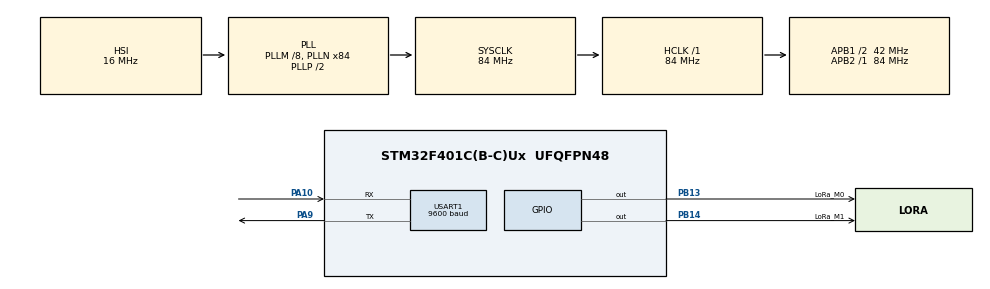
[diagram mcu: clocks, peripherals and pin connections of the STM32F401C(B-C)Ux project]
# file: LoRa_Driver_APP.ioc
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Dma.Request0=USART1_RX
Dma.USART1_RX.0.Direction=DMA_PERIPH_TO_MEMORY
Dma.USART1_RX.0.FIFOMode=DMA_FIFOMODE_DISABLE
Dma.USART1_RX.0.Instance=DMA2_Stream2
Dma.USART1_RX.0.MemDataAlignment=DMA_MDATAALIGN_BYTE
Dma.USART1_RX.0.MemInc=DMA_MINC_ENABLE
Dma.USART1_RX.0.Mode=DMA_NORMAL
Dma.USART1_RX.0.PeriphDataAlignment=DMA_PDATAALIGN_BYTE
Dma.USART1_RX.0.PeriphInc=DMA_PINC_DISABLE
Dma.USART1_RX.0.Priority=DMA_PRIORITY_LOW
Mcu.Family=STM32F4
Mcu.Name=STM32F401C(B-C)Ux
Mcu.Package=UFQFPN48
NVIC.DMA2_Stream2_IRQn=true\:0\:0\:false\:false\:true\:false\:true\:true
NVIC.PriorityGroup=NVIC_PRIORITYGROUP_4
NVIC.USART1_IRQn=true\:0\:0\:false\:false\:true\:true\:true\:true
PA10.Mode=Asynchronous
PA10.Signal=USART1_RX
PA13.Mode=Serial_Wire
PA13.Signal=SYS_JTMS-SWDIO
PA14.Mode=Serial_Wire
PA14.Signal=SYS_JTCK-SWCLK
PA9.Mode=Asynchronous
PA9.Signal=USART1_TX
PB13.GPIO_Label=LoRa_M0
PB13.Signal=GPIO_Output
PB14.GPIO_Label=LoRa_M1
PB14.Signal=GPIO_Output
PH0\ -\ OSC_IN.Mode=HSE-External-Oscillator
PH0\ -\ OSC_IN.Signal=RCC_OSC_IN
PH1\ -\ OSC_OUT.Mode=HSE-External-Oscillator
PH1\ -\ OSC_OUT.Signal=RCC_OSC_OUT
ProjectManager.HeapSize=0x200
ProjectManager.StackSize=0x400
ProjectManager.TargetToolchain=STM32CubeIDE
RCC.48MHZClocksFreq_Value=42000000
RCC.AHBFreq_Value=84000000
RCC.APB1CLKDivider=RCC_HCLK_DIV2
RCC.APB1Freq_Value=42000000
RCC.APB1TimFreq_Value=84000000
RCC.APB2Freq_Value=84000000
RCC.APB2TimFreq_Value=84000000
RCC.CortexFreq_Value=84000000
RCC.HCLKFreq_Value=84000000
RCC.HSE_VALUE=25000000
RCC.HSI_VALUE=16000000
RCC.LSE_VALUE=32768
RCC.PLLM=8
RCC.PLLN=84
RCC.SYSCLKFreq_VALUE=84000000
RCC.SYSCLKSource=RCC_SYSCLKSOURCE_PLLCLK
RCC.VCOOutputFreq_Value=168000000
USART1.BaudRate=9600
USART1.VirtualMode=VM_ASYNC
board=custom

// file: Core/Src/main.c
/* USER CODE BEGIN Header */
/**
  ******************************************************************************
  * @file           : main.c
  * @brief          : Main program body
  ******************************************************************************
  * @attention
  *
  * Copyright (c) 2024 STMicroelectronics.
  * All rights reserved.
  *
  * This software is licensed under terms that can be found in the LICENSE file
  * in the root directory of this software component.
  * If no LICENSE file comes with this software, it is provided AS-IS.
  *
  ******************************************************************************
  */
/* USER CODE END Header */
#include "main.h"

/* USER CODE BEGIN Includes */
#include "SubSys_WirelessCom_Config.h"
#include "SubSys_WirelessCom_App.h"
/* USER CODE END Includes */

UART_HandleTypeDef huart1;
DMA_HandleTypeDef hdma_usart1_rx;

/* USER CODE BEGIN PV */

	/*! We create 2 object for subsystem wireless communication,
	 * 	one of them is about configuration setting of wirelesscom device
	 * 	other one is about application object
	 */
	SubSys_WirelesscomConfig_HandleTypeDef dev_WirelessComConfig;
	SubSys_WirelessCom_APP_HandleTypeDef dev_WirelessComApp;

/* USER CODE END PV */

void SystemClock_Config(void);
static void MX_GPIO_Init(void);
static void MX_DMA_Init(void);
static void MX_USART1_UART_Init(void);

int main(void)
{

  /* MCU Configuration--------------------------------------------------------*/

  /* Reset of all peripherals, Initializes the Flash interface and the Systick. */
  HAL_Init();

  /* Configure the system clock */
  SystemClock_Config();

  /* Initialize all configured peripherals */
  MX_GPIO_Init();
  MX_DMA_Init();
  MX_USART1_UART_Init();
  /* USER CODE BEGIN 2 */

  /*-------------WIRELESS COMMUNICATION INITIALIZE PART BEGIN----------------*/

  	  /**
  	   * @brief : First of all, we upload initial settings into the wireless communication device.
  	   * 		  After that, we determine Target Address high and low byte and Target Channel.
  	   * 		  Some LoRa module has two pin as named M0 and M1. These provides selecting working mode
  	   * 		  For E220400T30 are M0 and M1 pins.
  	   * @note  : If you use dma for receiving and transmiting, fill it parameters that
  		  		  come after channel info
  	   */
    		#ifdef SAT_PERIPHERALS_LIB_INC_SUBSYS_WIRELESSCOM_CONFIG_H_

    	  	  dev_WirelessComConfig.interface.huart = &huart1;
    	  	  dev_WirelessComConfig.interface.GPIOx = GPIOA;
    	  	  dev_WirelessComConfig.LORA_PIN_M0= GPIO_PIN_12;
    	  	  dev_WirelessComConfig.LORA_PIN_M1= GPIO_PIN_11;
    	  	  dev_WirelessComConfig.Mode_SW = DeepSleep; 		/*! Module goes to sleep, that provides you to configure settings */
    	  	  dev_WirelessComConfig.interface.hdma_usart_rx = &hdma_usart1_rx;

    	  	  //HAL_UARTEx_ReceiveToIdle_DMA(dev_WirelessComConfig.interface.huart, ParamsLoraToBeGet, sizeof(ParamsLoraToBeGet));

    		  SubSys_WirelessCom_Config_Init(&dev_WirelessComConfig);

    		#endif

  //  		#ifdef SAT_PERIPHERALS_LIB_INC_SUBSYS_WIRELESSCOM_APP_H_
  //
  //  		  /*! Will be filled for your dev that use now*/
  //  		  dev_WirelessComApp.huartX = &huart1;
  //		  dev_WirelessComConfig.Mode_SW = NormalMode; 		/*! UART and wireless channel are open, transparent transmission is on*/
  //		  SubSys_WirelessCom_Config_WORK_MODE(&dev_WirelessComConfig);
  //
  //  		  /*! Will be filled for the PAYLOAD(Target) Device */
  //  		  dev_WirelessComApp.Target_ADDH = 0x14;
  //  		  dev_WirelessComApp.Target_ADDL = 0x53;
  //  		  dev_WirelessComApp.Target_Ch   = 0x22;
  //
  //  		#endif

  /*-------------WIRELESS COMMUNICATION INITIALIZE PART END----------------*/

  /* USER CODE END 2 */

  /* Infinite loop */
  /* USER CODE BEGIN WHILE */
  while (1)
  {

	  //HAL_UART_RxCpltCallback GELİNCE İNTERRUPTA SOKUP VERİYİ BİR BASACAN KAR�?IYAA

	  //while sonunda taşıyıcı gönderim yapacak sadece,
	  //while sonunda payload gönderim yapacak sadece ama arka planda veri gelirse ya interrupt ile hızlıca alacak(taşıycı ya da istasyon) ki
	  // veri alımı için istasyon 1 numaralı öncelik olamlı taşıyıcı 2 numaralı öncelik olmalı , veri gelince interruptı bulaştırmadan dma üzerinden akıp akmadığını kontrol edeceğiz

	  //İstasyon ise veri geldikçe kesmeye girecek veriyi alacak interrupt dma kullan , herhangi bir whilede olmayacak,
	  // ama komut gönderilirmek istenirse kesmeye gidip komutu hızlıca halletmesi lazım

	  /**
	   * Özet olarak  taşıyıcıdan görevyüküne olann kodlarda sadece whilede döngü sonunda wireless_transmit fonkyonu çalışmalı
	   * bu klasörü taşıyıcı kodundaymış gibi düşün , daha sonra payload açıkmış gibi düşünülecek
	   */

	  // örnek  taşıyıcı için kodu için

	  // fonk1_ms5611 verilerini al
	  // fonk2_batarya verilerini al
	  // fonk3_gps verilerini al
	  // fonk4_filtreleme yap
	  // fonk5_sd kart içine kaydet
	  // 1 saniye kadar bekle
	  // fonk6_lora verileri karşı hedefe gönder
	  /**
	   * fonk6_lora için neler kullanılacak hangi değişkenler rol oynayacak
	   *
	   *
	   */
	  SubSys_WirelessCom_Telemetry_Transfer_From_To(Sat_Carrier, Sat_Payload, &dev_WirelessComApp);
    /* USER CODE END WHILE */

  }
}

void SystemClock_Config(void)
{
  RCC_OscInitTypeDef RCC_OscInitStruct = {0};
  RCC_ClkInitTypeDef RCC_ClkInitStruct = {0};

  /** Configure the main internal regulator output voltage
  */
  __HAL_RCC_PWR_CLK_ENABLE();
  __HAL_PWR_VOLTAGESCALING_CONFIG(PWR_REGULATOR_VOLTAGE_SCALE2);

  /** Initializes the RCC Oscillators according to the specified parameters
  * in the RCC_OscInitTypeDef structure.
  */
  RCC_OscInitStruct.OscillatorType = RCC_OSCILLATORTYPE_HSI;
  RCC_OscInitStruct.HSIState = RCC_HSI_ON;
  RCC_OscInitStruct.HSICalibrationValue = RCC_HSICALIBRATION_DEFAULT;
  RCC_OscInitStruct.PLL.PLLState = RCC_PLL_ON;
  RCC_OscInitStruct.PLL.PLLSource = RCC_PLLSOURCE_HSI;
  RCC_OscInitStruct.PLL.PLLM = 8;
  RCC_OscInitStruct.PLL.PLLN = 84;
  RCC_OscInitStruct.PLL.PLLP = RCC_PLLP_DIV2;
  RCC_OscInitStruct.PLL.PLLQ = 4;
  if (HAL_RCC_OscConfig(&RCC_OscInitStruct) != HAL_OK)
  {
    Error_Handler();
  }

  /** Initializes the CPU, AHB and APB buses clocks
  */
  RCC_ClkInitStruct.ClockType = RCC_CLOCKTYPE_HCLK|RCC_CLOCKTYPE_SYSCLK
                              |RCC_CLOCKTYPE_PCLK1|RCC_CLOCKTYPE_PCLK2;
  RCC_ClkInitStruct.SYSCLKSource = RCC_SYSCLKSOURCE_PLLCLK;
  RCC_ClkInitStruct.AHBCLKDivider = RCC_SYSCLK_DIV1;
  RCC_ClkInitStruct.APB1CLKDivider = RCC_HCLK_DIV2;
  RCC_ClkInitStruct.APB2CLKDivider = RCC_HCLK_DIV1;

  if (HAL_RCC_ClockConfig(&RCC_ClkInitStruct, FLASH_LATENCY_2) != HAL_OK)
  {
    Error_Handler();
  }
}

static void MX_USART1_UART_Init(void)
{

  huart1.Instance = USART1;
  huart1.Init.BaudRate = 9600;
  huart1.Init.WordLength = UART_WORDLENGTH_8B;
  huart1.Init.StopBits = UART_STOPBITS_1;
  huart1.Init.Parity = UART_PARITY_NONE;
  huart1.Init.Mode = UART_MODE_TX_RX;
  huart1.Init.HwFlowCtl = UART_HWCONTROL_NONE;
  huart1.Init.OverSampling = UART_OVERSAMPLING_16;
  if (HAL_UART_Init(&huart1) != HAL_OK)
  {
    Error_Handler();
  }

}

static void MX_DMA_Init(void)
{

  /* DMA controller clock enable */
  __HAL_RCC_DMA2_CLK_ENABLE();

  /* DMA interrupt init */
  /* DMA2_Stream2_IRQn interrupt configuration */
  HAL_NVIC_SetPriority(DMA2_Stream2_IRQn, 0, 0);
  HAL_NVIC_EnableIRQ(DMA2_Stream2_IRQn);

}

static void MX_GPIO_Init(void)
{
  GPIO_InitTypeDef GPIO_InitStruct = {0};

  /* GPIO Ports Clock Enable */
  __HAL_RCC_GPIOH_CLK_ENABLE();
  __HAL_RCC_GPIOB_CLK_ENABLE();
  __HAL_RCC_GPIOA_CLK_ENABLE();

  /*Configure GPIO pin Output Level */
  HAL_GPIO_WritePin(GPIOB, LoRa_M0_Pin|LoRa_M1_Pin, GPIO_PIN_RESET);

  /*Configure GPIO pins : LoRa_M0_Pin LoRa_M1_Pin */
  GPIO_InitStruct.Pin = LoRa_M0_Pin|LoRa_M1_Pin;
  GPIO_InitStruct.Mode = GPIO_MODE_OUTPUT_PP;
  GPIO_InitStruct.Pull = GPIO_NOPULL;
  GPIO_InitStruct.Speed = GPIO_SPEED_FREQ_LOW;
  HAL_GPIO_Init(GPIOB, &GPIO_InitStruct);

}

void Error_Handler(void)
{
  __disable_irq();
  while (1)
  {
  }
}
